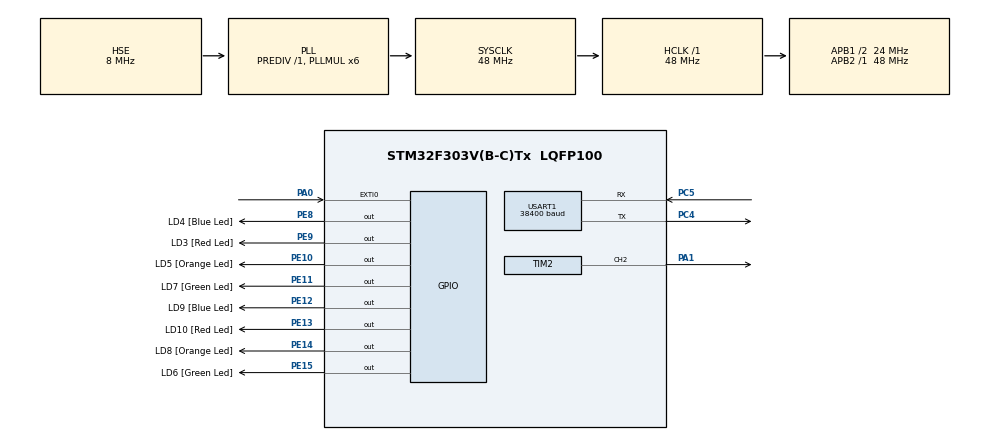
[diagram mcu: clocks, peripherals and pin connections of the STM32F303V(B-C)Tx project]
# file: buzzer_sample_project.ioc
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Mcu.Family=STM32F3
Mcu.Name=STM32F303V(B-C)Tx
Mcu.Package=LQFP100
NVIC.PriorityGroup=NVIC_PRIORITYGROUP_0
NVIC.TIM1_BRK_TIM15_IRQn=true\:0\:0\:false\:false\:true\:true\:true\:true
NVIC.TIM1_CC_IRQn=true\:0\:0\:false\:false\:true\:true\:true\:true
NVIC.TIM1_TRG_COM_TIM17_IRQn=true\:0\:0\:false\:false\:true\:true\:true\:true
NVIC.TIM1_UP_TIM16_IRQn=true\:0\:0\:false\:false\:true\:true\:true\:true
NVIC.USART1_IRQn=true\:0\:0\:false\:false\:true\:true\:true\:true
PA0.GPIO_PuPd=GPIO_PULLDOWN
PA0.Signal=GPXTI0
PA1.Signal=S_TIM2_CH2
PA13.GPIO_Label=SWDIO
PA13.Mode=Serial_Wire
PA13.Signal=SYS_JTMS-SWDIO
PA14.GPIO_Label=SWCLK
PA14.Mode=Serial_Wire
PA14.Signal=SYS_JTCK-SWCLK
PB3.GPIO_Label=SWO
PB3.Signal=SYS_JTDO-TRACESWO
PC14-OSC32_IN.GPIO_Label=OSC32_IN
PC14-OSC32_IN.Signal=RCC_OSC32_IN
PC15-OSC32_OUT.GPIO_Label=OSC32_OUT
PC15-OSC32_OUT.Signal=RCC_OSC32_OUT
PC4.Mode=Asynchronous
PC4.Signal=USART1_TX
PC5.Mode=Asynchronous
PC5.Signal=USART1_RX
PE10.GPIO_Label=LD5 [Orange Led]
PE10.Signal=GPIO_Output
PE11.GPIO_Label=LD7 [Green Led]
PE11.Signal=GPIO_Output
PE12.GPIO_Label=LD9 [Blue Led]
PE12.Signal=GPIO_Output
PE13.GPIO_Label=LD10 [Red Led]
PE13.Signal=GPIO_Output
PE14.GPIO_Label=LD8 [Orange Led]
PE14.Signal=GPIO_Output
PE15.GPIO_Label=LD6 [Green Led]
PE15.Signal=GPIO_Output
PE8.GPIO_Label=LD4 [Blue Led]
PE8.Signal=GPIO_Output
PE9.GPIO_Label=LD3 [Red Led]
PE9.Signal=GPIO_Output
PF0-OSC_IN.GPIO_Label=OSC_IN
PF0-OSC_IN.Mode=HSE-External-Clock-Source
PF0-OSC_IN.Signal=RCC_OSC_IN
PF1-OSC_OUT.GPIO_Label=OSC_OUT
PF1-OSC_OUT.Signal=RCC_OSC_OUT
ProjectManager.HeapSize=0x200
ProjectManager.StackSize=0x400
ProjectManager.TargetToolchain=STM32CubeIDE
RCC.AHBFreq_Value=48000000
RCC.APB1CLKDivider=RCC_HCLK_DIV2
RCC.APB1Freq_Value=24000000
RCC.APB1TimFreq_Value=48000000
RCC.APB2Freq_Value=48000000
RCC.APB2TimFreq_Value=48000000
RCC.CortexFreq_Value=48000000
RCC.HCLKFreq_Value=48000000
RCC.HSE_VALUE=8000000
RCC.HSI_VALUE=8000000
RCC.LSE_VALUE=32768
RCC.PLLMUL=RCC_PLL_MUL6
RCC.PLLSourceVirtual=RCC_PLLSOURCE_HSE
RCC.SYSCLKFreq_VALUE=48000000
RCC.SYSCLKSourceVirtual=RCC_SYSCLKSOURCE_PLLCLK
RCC.USBFreq_Value=48000000
SH.S_TIM2_CH2.0=TIM2_CH2,PWM Generation2 CH2
TIM1.Period=1000-1
TIM1.Prescaler=48-1
TIM2.Channel-PWM\ Generation2\ CH2=TIM_CHANNEL_2
TIM2.Period=1000000-1
TIM2.Prescaler=23
USART1.BaudRate=38400
USART1.VirtualMode-Asynchronous=VM_ASYNC
VP_TIM1_VS_ClockSourceINT.Mode=Internal
VP_TIM2_VS_ClockSourceINT.Mode=Internal
board=STM32F3DISCOVERY

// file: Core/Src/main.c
/* USER CODE BEGIN Header */
/**
  ******************************************************************************
  * @file           : main.c
  * @brief          : Main program body
  ******************************************************************************
  * @attention
  *
  * <h2><center>&copy; Copyright (c) 2021 STMicroelectronics.
  * All rights reserved.</center></h2>
  *
  * This software component is licensed by ST under BSD 3-Clause license,
  * the "License"; You may not use this file except in compliance with the
  * License. You may obtain a copy of the License at:
  *                        opensource.org/licenses/BSD-3-Clause
  *
  ******************************************************************************
  */
/* USER CODE END Header */
#include "main.h"

TIM_HandleTypeDef htim1;
TIM_HandleTypeDef htim2;

UART_HandleTypeDef huart1;

void SystemClock_Config(void);
static void MX_GPIO_Init(void);
static void MX_TIM2_Init(void);
static void MX_USART1_UART_Init(void);
static void MX_TIM1_Init(void);

int main(void)
{

  /* MCU Configuration--------------------------------------------------------*/

  /* Reset of all peripherals, Initializes the Flash interface and the Systick. */
  HAL_Init();

  /* Configure the system clock */
  SystemClock_Config();

  /* Initialize all configured peripherals */
  MX_GPIO_Init();
  MX_TIM2_Init();
  MX_USART1_UART_Init();
  MX_TIM1_Init();
  /* USER CODE BEGIN 2 */
  uart_rx_enable_it();
  PWM_Start();
  HAL_TIM_Base_Start(&htim1);
  /* USER CODE END 2 */

  /* Infinite loop */
  while (1)
  {

  }
}

void SystemClock_Config(void)
{
  RCC_OscInitTypeDef RCC_OscInitStruct = {0};
  RCC_ClkInitTypeDef RCC_ClkInitStruct = {0};
  RCC_PeriphCLKInitTypeDef PeriphClkInit = {0};

  /** Initializes the RCC Oscillators according to the specified parameters
  * in the RCC_OscInitTypeDef structure.
  */
  RCC_OscInitStruct.OscillatorType = RCC_OSCILLATORTYPE_HSE;
  RCC_OscInitStruct.HSEState = RCC_HSE_BYPASS;
  RCC_OscInitStruct.HSEPredivValue = RCC_HSE_PREDIV_DIV1;
  RCC_OscInitStruct.HSIState = RCC_HSI_ON;
  RCC_OscInitStruct.PLL.PLLState = RCC_PLL_ON;
  RCC_OscInitStruct.PLL.PLLSource = RCC_PLLSOURCE_HSE;
  RCC_OscInitStruct.PLL.PLLMUL = RCC_PLL_MUL6;
  if (HAL_RCC_OscConfig(&RCC_OscInitStruct) != HAL_OK)
  {
    Error_Handler();
  }

  /** Initializes the CPU, AHB and APB buses clocks
  */
  RCC_ClkInitStruct.ClockType = RCC_CLOCKTYPE_HCLK|RCC_CLOCKTYPE_SYSCLK
                              |RCC_CLOCKTYPE_PCLK1|RCC_CLOCKTYPE_PCLK2;
  RCC_ClkInitStruct.SYSCLKSource = RCC_SYSCLKSOURCE_PLLCLK;
  RCC_ClkInitStruct.AHBCLKDivider = RCC_SYSCLK_DIV1;
  RCC_ClkInitStruct.APB1CLKDivider = RCC_HCLK_DIV2;
  RCC_ClkInitStruct.APB2CLKDivider = RCC_HCLK_DIV1;

  if (HAL_RCC_ClockConfig(&RCC_ClkInitStruct, FLASH_LATENCY_1) != HAL_OK)
  {
    Error_Handler();
  }
  PeriphClkInit.PeriphClockSelection = RCC_PERIPHCLK_USART1|RCC_PERIPHCLK_TIM1;
  PeriphClkInit.Usart1ClockSelection = RCC_USART1CLKSOURCE_PCLK2;
  PeriphClkInit.Tim1ClockSelection = RCC_TIM1CLK_HCLK;
  if (HAL_RCCEx_PeriphCLKConfig(&PeriphClkInit) != HAL_OK)
  {
    Error_Handler();
  }
}

static void MX_TIM1_Init(void)
{

  TIM_ClockConfigTypeDef sClockSourceConfig = {0};
  TIM_MasterConfigTypeDef sMasterConfig = {0};

  htim1.Instance = TIM1;
  htim1.Init.Prescaler = 48-1;
  htim1.Init.CounterMode = TIM_COUNTERMODE_UP;
  htim1.Init.Period = 1000-1;
  htim1.Init.ClockDivision = TIM_CLOCKDIVISION_DIV1;
  htim1.Init.RepetitionCounter = 0;
  htim1.Init.AutoReloadPreload = TIM_AUTORELOAD_PRELOAD_DISABLE;
  if (HAL_TIM_Base_Init(&htim1) != HAL_OK)
  {
    Error_Handler();
  }
  sClockSourceConfig.ClockSource = TIM_CLOCKSOURCE_INTERNAL;
  if (HAL_TIM_ConfigClockSource(&htim1, &sClockSourceConfig) != HAL_OK)
  {
    Error_Handler();
  }
  sMasterConfig.MasterOutputTrigger = TIM_TRGO_RESET;
  sMasterConfig.MasterOutputTrigger2 = TIM_TRGO2_RESET;
  sMasterConfig.MasterSlaveMode = TIM_MASTERSLAVEMODE_DISABLE;
  if (HAL_TIMEx_MasterConfigSynchronization(&htim1, &sMasterConfig) != HAL_OK)
  {
    Error_Handler();
  }

}

static void MX_TIM2_Init(void)
{

  TIM_ClockConfigTypeDef sClockSourceConfig = {0};
  TIM_MasterConfigTypeDef sMasterConfig = {0};
  TIM_OC_InitTypeDef sConfigOC = {0};

  htim2.Instance = TIM2;
  htim2.Init.Prescaler = 23;
  htim2.Init.CounterMode = TIM_COUNTERMODE_UP;
  htim2.Init.Period = 1000000-1;
  htim2.Init.ClockDivision = TIM_CLOCKDIVISION_DIV1;
  htim2.Init.AutoReloadPreload = TIM_AUTORELOAD_PRELOAD_DISABLE;
  if (HAL_TIM_Base_Init(&htim2) != HAL_OK)
  {
    Error_Handler();
  }
  sClockSourceConfig.ClockSource = TIM_CLOCKSOURCE_INTERNAL;
  if (HAL_TIM_ConfigClockSource(&htim2, &sClockSourceConfig) != HAL_OK)
  {
    Error_Handler();
  }
  if (HAL_TIM_PWM_Init(&htim2) != HAL_OK)
  {
    Error_Handler();
  }
  sMasterConfig.MasterOutputTrigger = TIM_TRGO_RESET;
  sMasterConfig.MasterSlaveMode = TIM_MASTERSLAVEMODE_DISABLE;
  if (HAL_TIMEx_MasterConfigSynchronization(&htim2, &sMasterConfig) != HAL_OK)
  {
    Error_Handler();
  }
  sConfigOC.OCMode = TIM_OCMODE_PWM1;
  sConfigOC.Pulse = 0;
  sConfigOC.OCPolarity = TIM_OCPOLARITY_HIGH;
  sConfigOC.OCFastMode = TIM_OCFAST_DISABLE;
  if (HAL_TIM_PWM_ConfigChannel(&htim2, &sConfigOC, TIM_CHANNEL_2) != HAL_OK)
  {
    Error_Handler();
  }
  HAL_TIM_MspPostInit(&htim2);

}

static void MX_USART1_UART_Init(void)
{

  huart1.Instance = USART1;
  huart1.Init.BaudRate = 38400;
  huart1.Init.WordLength = UART_WORDLENGTH_8B;
  huart1.Init.StopBits = UART_STOPBITS_1;
  huart1.Init.Parity = UART_PARITY_NONE;
  huart1.Init.Mode = UART_MODE_TX_RX;
  huart1.Init.HwFlowCtl = UART_HWCONTROL_NONE;
  huart1.Init.OverSampling = UART_OVERSAMPLING_16;
  huart1.Init.OneBitSampling = UART_ONE_BIT_SAMPLE_DISABLE;
  huart1.AdvancedInit.AdvFeatureInit = UART_ADVFEATURE_NO_INIT;
  if (HAL_UART_Init(&huart1) != HAL_OK)
  {
    Error_Handler();
  }

}

static void MX_GPIO_Init(void)
{
  GPIO_InitTypeDef GPIO_InitStruct = {0};

  /* GPIO Ports Clock Enable */
  __HAL_RCC_GPIOC_CLK_ENABLE();
  __HAL_RCC_GPIOF_CLK_ENABLE();
  __HAL_RCC_GPIOA_CLK_ENABLE();
  __HAL_RCC_GPIOE_CLK_ENABLE();
  __HAL_RCC_GPIOB_CLK_ENABLE();

  /*Configure GPIO pin Output Level */
  HAL_GPIO_WritePin(GPIOE, LD4_Pin|LD3_Pin|LD5_Pin|LD7_Pin
                          |LD9_Pin|LD10_Pin|LD8_Pin|LD6_Pin, GPIO_PIN_RESET);

  /*Configure GPIO pin : PA0 */
  GPIO_InitStruct.Pin = GPIO_PIN_0;
  GPIO_InitStruct.Mode = GPIO_MODE_IT_RISING;
  GPIO_InitStruct.Pull = GPIO_PULLDOWN;
  HAL_GPIO_Init(GPIOA, &GPIO_InitStruct);

  /*Configure GPIO pins : LD4_Pin LD3_Pin LD5_Pin LD7_Pin
                           LD9_Pin LD10_Pin LD8_Pin LD6_Pin */
  GPIO_InitStruct.Pin = LD4_Pin|LD3_Pin|LD5_Pin|LD7_Pin
                          |LD9_Pin|LD10_Pin|LD8_Pin|LD6_Pin;
  GPIO_InitStruct.Mode = GPIO_MODE_OUTPUT_PP;
  GPIO_InitStruct.Pull = GPIO_NOPULL;
  GPIO_InitStruct.Speed = GPIO_SPEED_FREQ_LOW;
  HAL_GPIO_Init(GPIOE, &GPIO_InitStruct);

}

void Error_Handler(void)
{
  __disable_irq();
  while (1)
  {
  }
}
